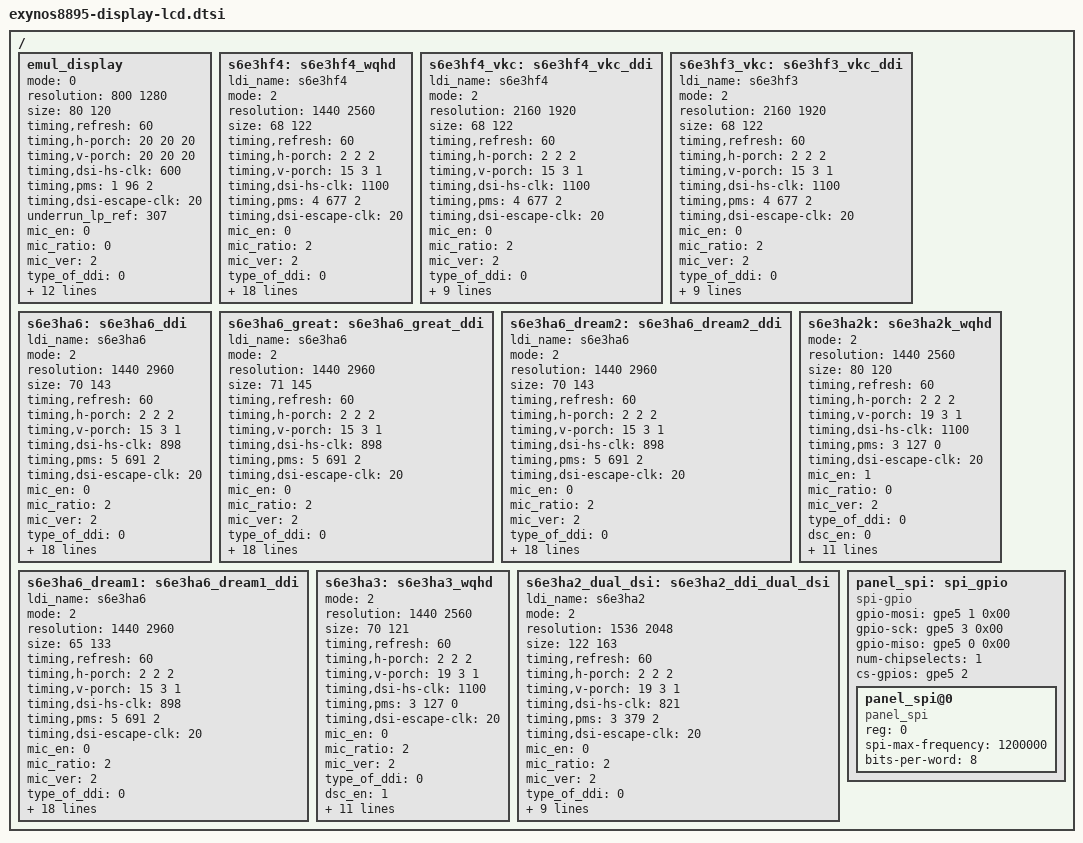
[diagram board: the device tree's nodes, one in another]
/*
 * SAMSUNG LCD Panel Device Tree Source
 *
 * Copyright (c) 2016 Samsung Electronics Co., Ltd.
 *		http://www.samsung.com
 *
 * This program is free software; you can redistribute it and/or modify
 * it under the terms of the GNU General Public License version 2 as
 * published by the Free Software Foundation.
*/

/ {
	emul_display: emul_display {
		mode = <0>; /* 0: video mode, 1: DP command mode, 2: MIPI command mode */
		resolution = <800 1280>;
		size = <80 120>;
		timing,refresh = <60>;
		timing,h-porch = <20 20 20>;
		timing,v-porch = <20 20 20>;
		timing,dsi-hs-clk = <600>;
		/* TODO : pms value to be set */
		timing,pms = <1 96 2>;
		timing,dsi-escape-clk = <20>;
		underrun_lp_ref = <307>;
		mic_en = <0>;		/* 0: Disable, 1: Enable */
		mic_ratio = <0>;	/* 0: 1/2 mic, 1: 1/3 mic */
		mic_ver = <2>;		/* 0: mic v1.1, 1: v1.2, 2: v2.0 */
		type_of_ddi = <0>;	/* 0: Samsung Mobile, 1: MAGNA, 2: Normal(Etc) */
		dsc_en = <0>;		/* 0: Disable, 1: Enable */
		dsc_cnt = <0>;		/* used DSC count */
		dsc_slice_num = <0>;	/* count of dsc slice */
		data_lane = <4>;	/* number of using data lane */
		cmd_underrun_lp_ref = <1203>;	/* for underrun detect at command mode*/
		vt_compensation = <2871>;	/* for underrun detect at video mode*/
		dsu_en = <0>;
		hdr_num = <0>;		/* max: 4 */
		hdr_type = <0 0 0 0>;	/* 1: DOLBY_VISION, 2: HDR10, 3: HLG */
		hdr_max_luma = <0>;		/* 0 */
		hdr_max_avg_luma = <0>;	/* 0 */
		hdr_min_luma = <0>;		/* 0.0000 */
	};

	s6e3hf4: s6e3hf4_wqhd {
		ldi_name = "s6e3hf4";
		mode = <2>;		/* 0: video mode, 1: DP command mode, 2: MIPI command mode */
		resolution = <1440 2560>;
		size = <68 122>;
		timing,refresh = <60>;
		timing,h-porch = <2 2 2>;
		timing,v-porch = <15 3 1>;
		timing,dsi-hs-clk = <1100>;
		timing,pms = <4 677 2>;
		timing,dsi-escape-clk = <20>;
		mic_en = <0>;		/* 0: Disable, 1: Enable */
		mic_ratio = <2>;	/* 0: 1/2 mic, 1: 1/3 mic */
		mic_ver = <2>;		/* 0: mic v1.1, 1: v1.2, 2: v2.0 */
		type_of_ddi = <0>;	/* 0: Samsung Mobile, 1: MAGNA, 2: Normal(Etc) */
		dsc_en = <1>;		/* 0: Disable, 1: Enable */
		dsc_cnt = <2>;		/* used DSC count */
		dsc_slice_num = <4>;	/* count of dsc slice */
		dsc_slice_h = <64>;	/* height of dsc slice */
		data_lane = <4>;	/* number of using data lane */
		cmd_underrun_lp_ref = <5629>;	/* for underrun detect*/
		dsu_en = <1>;
		dsu_number = <3>;
		dsu_width = <1440 1080 720>;
		dsu_height = <2560 1920 1280>;
		dsu_dsc_width = <720 540 360>;
		dsu_dsc_height = <64 64 128>;
		dsu_dsc_en = <1 1 1>;
		hdr_num = <1>;		/* max: 4 */
		hdr_type = <2 0 0 0>;	/* 1: DOLBY_VISION, 2: HDR10, 3: HLG */
		hdr_max_luma = <5400000>;		/* 540 */
		hdr_max_avg_luma = <1200000>;	/* 120 */
		hdr_min_luma = <5>;				/* 0.0005 */
	};

	s6e3hf4_vkc: s6e3hf4_vkc_ddi {
		ldi_name = "s6e3hf4";
		mode = <2>;		/* 0: video mode, 1: DP command mode, 2: MIPI command mode */
		resolution = <2160 1920>;
		size = <68 122>;
		timing,refresh = <60>;
		timing,h-porch = <2 2 2>;
		timing,v-porch = <15 3 1>;
		timing,dsi-hs-clk = <1100>;
		timing,pms = <4 677 2>;
		timing,dsi-escape-clk = <20>;
		mic_en = <0>;		/* 0: Disable, 1: Enable */
		mic_ratio = <2>;	/* 0: 1/2 mic, 1: 1/3 mic */
		mic_ver = <2>;		/* 0: mic v1.1, 1: v1.2, 2: v2.0 */
		type_of_ddi = <0>;	/* 0: Samsung Mobile, 1: MAGNA, 2: Normal(Etc) */
		dsc_en = <1>;		/* 0: Disable, 1: Enable */
		dsc_cnt = <2>;		/* used DSC count */
		dsc_slice_num = <2>;	/* count of dsc slice */
		dsc_slice_h = <32>;	/* height of dsc slice */
		data_lane = <4>;	/* number of using data lane */
		cmd_underrun_lp_ref = <5629>;	/* for underrun detect*/
		dsu_en = <0>;
		op_mode = <1>; /*0:Single Display + Single DSI, 1: Dual Display + Dual DSI, 2 : single Display + Dual DSI*/
		ss_path_swap = <1>;
	};


	s6e3hf3_vkc: s6e3hf3_vkc_ddi {
		ldi_name = "s6e3hf3";
		mode = <2>;		/* 0: video mode, 1: DP command mode, 2: MIPI command mode */
		resolution = <2160 1920>;
		size = <68 122>;
		timing,refresh = <60>;
		timing,h-porch = <2 2 2>;
		timing,v-porch = <15 3 1>;
		timing,dsi-hs-clk = <1100>;
		timing,pms = <4 677 2>;
		timing,dsi-escape-clk = <20>;
		mic_en = <0>;		/* 0: Disable, 1: Enable */
		mic_ratio = <2>;	/* 0: 1/2 mic, 1: 1/3 mic */
		mic_ver = <2>;		/* 0: mic v1.1, 1: v1.2, 2: v2.0 */
		type_of_ddi = <0>;	/* 0: Samsung Mobile, 1: MAGNA, 2: Normal(Etc) */
		dsc_en = <0>;		/* 0: Disable, 1: Enable */
		dsc_cnt = <2>;		/* used DSC count */
		dsc_slice_num = <2>;	/* count of dsc slice */
		dsc_slice_h = <32>;	/* height of dsc slice */
		data_lane = <4>;	/* number of using data lane */
		cmd_underrun_lp_ref = <5629>;	/* for underrun detect*/
		dsu_en = <0>;
		op_mode = <1>; /*0:Single Display + Single DSI, 1: Dual Display + Dual DSI, 2 : single Display + Dual DSI*/
		ss_path_swap = <1>;
	};


	s6e3ha6: s6e3ha6_ddi {
		ldi_name = "s6e3ha6";
		mode = <2>;		/* 0: video mode, 1: DP command mode, 2: MIPI command mode */
		resolution = <1440 2960>;
		size = <70 143>;
		timing,refresh = <60>;
		timing,h-porch = <2 2 2>;
		timing,v-porch = <15 3 1>;
		timing,dsi-hs-clk = <898>;
		timing,pms = <5 691 2>;
		timing,dsi-escape-clk = <20>;
		mic_en = <0>;		/* 0: Disable, 1: Enable */
		mic_ratio = <2>;	/* 0: 1/2 mic, 1: 1/3 mic */
		mic_ver = <2>;		/* 0: mic v1.1, 1: v1.2, 2: v2.0 */
		type_of_ddi = <0>;	/* 0: Samsung Mobile, 1: MAGNA, 2: Normal(Etc) */
		dsc_en = <1>;		/* 0: Disable, 1: Enable */
		dsc_cnt = <2>;		/* used DSC count */
		dsc_slice_num = <2>;	/* count of dsc slice */
		dsc_slice_h = <40>;	/* height of dsc slice */
		data_lane = <4>;	/* number of using data lane */
		cmd_underrun_lp_ref = <3022>;	/* for underrun detect*/
		dsu_en = <1>;
		dsu_number = <3>;
		dsu_width = <1440 1080 720>;
		dsu_height = <2960 2220 1480>;
		dsu_dsc_width = <720 540 360>;
		dsu_dsc_height = <40 30 74>;
		dsu_dsc_en = <1 1 0>;
		hdr_num = <1>;		/* max: 4 */
		hdr_type = <2 0 0 0>;	/* 1: DOLBY_VISION, 2: HDR10, 3: HLG */
		hdr_max_luma = <5400000>;		/* 540 */
		hdr_max_avg_luma = <1200000>;	/* 120 */
		hdr_min_luma = <5>;				/* 0.0005 */
	};

	s6e3ha6_great: s6e3ha6_great_ddi {
		ldi_name = "s6e3ha6";
		mode = <2>;		/* 0: video mode, 1: DP command mode, 2: MIPI command mode */
		resolution = <1440 2960>;
		size = <71 145>;
		timing,refresh = <60>;
		timing,h-porch = <2 2 2>;
		timing,v-porch = <15 3 1>;
		timing,dsi-hs-clk = <898>;
		timing,pms = <5 691 2>;
		timing,dsi-escape-clk = <20>;
		mic_en = <0>;		/* 0: Disable, 1: Enable */
		mic_ratio = <2>;	/* 0: 1/2 mic, 1: 1/3 mic */
		mic_ver = <2>;		/* 0: mic v1.1, 1: v1.2, 2: v2.0 */
		type_of_ddi = <0>;	/* 0: Samsung Mobile, 1: MAGNA, 2: Normal(Etc) */
		dsc_en = <1>;		/* 0: Disable, 1: Enable */
		dsc_cnt = <2>;		/* used DSC count */
		dsc_slice_num = <2>;	/* count of dsc slice */
		dsc_slice_h = <40>;	/* height of dsc slice */
		data_lane = <4>;	/* number of using data lane */
		cmd_underrun_lp_ref = <3022>;	/* for underrun detect*/
		dsu_en = <1>;
		dsu_number = <3>;
		dsu_width = <1440 1080 720>;
		dsu_height = <2960 2220 1480>;
		dsu_dsc_width = <720 540 360>;
		dsu_dsc_height = <40 30 74>;
		dsu_dsc_en = <1 1 0>;
		hdr_num = <1>;		/* max: 4 */
		hdr_type = <2 0 0 0>;	/* 1: DOLBY_VISION, 2: HDR10, 3: HLG */
		hdr_max_luma = <5400000>;		/* 540 */
		hdr_max_avg_luma = <1200000>;	/* 120 */
		hdr_min_luma = <5>;				/* 0.0005 */
	};


	s6e3ha6_dream2: s6e3ha6_dream2_ddi {
		ldi_name = "s6e3ha6";
		mode = <2>;		/* 0: video mode, 1: DP command mode, 2: MIPI command mode */
		resolution = <1440 2960>;
		size = <70 143>;
		timing,refresh = <60>;
		timing,h-porch = <2 2 2>;
		timing,v-porch = <15 3 1>;
		timing,dsi-hs-clk = <898>;
		timing,pms = <5 691 2>;
		timing,dsi-escape-clk = <20>;
		mic_en = <0>;		/* 0: Disable, 1: Enable */
		mic_ratio = <2>;	/* 0: 1/2 mic, 1: 1/3 mic */
		mic_ver = <2>;		/* 0: mic v1.1, 1: v1.2, 2: v2.0 */
		type_of_ddi = <0>;	/* 0: Samsung Mobile, 1: MAGNA, 2: Normal(Etc) */
		dsc_en = <1>;		/* 0: Disable, 1: Enable */
		dsc_cnt = <2>;		/* used DSC count */
		dsc_slice_num = <2>;	/* count of dsc slice */
		dsc_slice_h = <40>;	/* height of dsc slice */
		data_lane = <4>;	/* number of using data lane */
		cmd_underrun_lp_ref = <3022>;	/* for underrun detect*/
		dsu_en = <1>;
		dsu_number = <3>;
		dsu_width = <1440 1080 720>;
		dsu_height = <2960 2220 1480>;
		dsu_dsc_width = <720 540 360>;
		dsu_dsc_height = <40 30 74>;
		dsu_dsc_en = <1 1 0>;
		hdr_num = <1>;		/* max: 4 */
		hdr_type = <2 0 0 0>;	/* 1: DOLBY_VISION, 2: HDR10, 3: HLG */
		hdr_max_luma = <5400000>;		/* 540 */
		hdr_max_avg_luma = <1200000>;	/* 120 */
		hdr_min_luma = <5>;				/* 0.0005 */
	};

	s6e3ha6_dream1: s6e3ha6_dream1_ddi {
		ldi_name = "s6e3ha6";
		mode = <2>;		/* 0: video mode, 1: DP command mode, 2: MIPI command mode */
		resolution = <1440 2960>;
		size = <65 133>;
		timing,refresh = <60>;
		timing,h-porch = <2 2 2>;
		timing,v-porch = <15 3 1>;
		timing,dsi-hs-clk = <898>;
		timing,pms = <5 691 2>;
		timing,dsi-escape-clk = <20>;
		mic_en = <0>;		/* 0: Disable, 1: Enable */
		mic_ratio = <2>;	/* 0: 1/2 mic, 1: 1/3 mic */
		mic_ver = <2>;		/* 0: mic v1.1, 1: v1.2, 2: v2.0 */
		type_of_ddi = <0>;	/* 0: Samsung Mobile, 1: MAGNA, 2: Normal(Etc) */
		dsc_en = <1>;		/* 0: Disable, 1: Enable */
		dsc_cnt = <2>;		/* used DSC count */
		dsc_slice_num = <2>;	/* count of dsc slice */
		dsc_slice_h = <40>;	/* height of dsc slice */
		data_lane = <4>;	/* number of using data lane */
		cmd_underrun_lp_ref = <3022>;	/* for underrun detect*/
		dsu_en = <1>;
		dsu_number = <3>;
		dsu_width = <1440 1080 720>;
		dsu_height = <2960 2220 1480>;
		dsu_dsc_width = <720 540 360>;
		dsu_dsc_height = <40 30 74>;
		dsu_dsc_en = <1 1 0>;
		hdr_num = <1>;		/* max: 4 */
		hdr_type = <2 0 0 0>;	/* 1: DOLBY_VISION, 2: HDR10, 3: HLG */
		hdr_max_luma = <5400000>;		/* 540 */
		hdr_max_avg_luma = <1200000>;	/* 120 */
		hdr_min_luma = <5>;				/* 0.0005 */
	};

	s6e3ha2k: s6e3ha2k_wqhd {
		mode = <2>;		/* 0: video mode, 1: DP command mode, 2: MIPI command mode */
		resolution = <1440 2560>;
		size = <80 120>;
		timing,refresh = <60>;
		timing,h-porch = <2 2 2>;
		timing,v-porch = <19 3 1>;
		timing,dsi-hs-clk = <1100>;
		timing,pms = <3 127 0>;
		timing,dsi-escape-clk = <20>;
		mic_en = <1>;		/* 0: Disable, 1: Enable */
		mic_ratio = <0>;	/* 0: 1/2 mic, 1: 1/3 mic */
		mic_ver = <2>;		/* 0: mic v1.1, 1: v1.2, 2: v2.0 */
		type_of_ddi = <0>;	/* 0: Samsung Mobile, 1: MAGNA, 2: Normal(Etc) */
		dsc_en = <0>;		/* 0: Disable, 1: Enable */
		dsc_cnt = <0>;		/* used DSC count */
		dsc_slice_num = <0>;	/* count of dsc slice */
		dsc_slice_h = <0>;	/* height of dsc slice */
		data_lane = <4>;	/* number of using data lane */
		cmd_underrun_lp_ref = <1203>;	/* for underrun detect*/
		dsu_en = <0>;
		hdr_num = <1>;		/* max: 4 */
		hdr_type = <2 0 0 0>;	/* 1: DOLBY_VISION, 2: HDR10, 3: HLG */
		hdr_max_luma = <5400000>;		/* 540 */
		hdr_max_avg_luma = <1200000>;	/* 120 */
		hdr_min_luma = <5>;				/* 0.0005 */
	};

	s6e3ha3: s6e3ha3_wqhd {
		mode = <2>;		/* 0: video mode, 1: DP command mode, 2: MIPI command mode */
		resolution = <1440 2560>;
		size = <70 121>;
		timing,refresh = <60>;
		timing,h-porch = <2 2 2>;
		timing,v-porch = <19 3 1>;
		timing,dsi-hs-clk = <1100>;
		timing,pms = <3 127 0>;
		timing,dsi-escape-clk = <20>;
		mic_en = <0>;		/* 0: Disable, 1: Enable */
		mic_ratio = <2>;	/* 0: 1/2 mic, 1: 1/3 mic */
		mic_ver = <2>;		/* 0: mic v1.1, 1: v1.2, 2: v2.0 */
		type_of_ddi = <0>;	/* 0: Samsung Mobile, 1: MAGNA, 2: Normal(Etc) */
		dsc_en = <1>;		/* 0: Disable, 1: Enable */
		dsc_cnt = <1>;		/* used DSC count */
		dsc_slice_num = <1>;	/* count of dsc slice */
		dsc_slice_h = <32>;	/* height of dsc slice */
		data_lane = <4>;	/* number of using data lane */
		cmd_underrun_lp_ref = <1203>;	/* for underrun detect*/
		dsu_en = <0>;
		hdr_num = <1>;		/* max: 4 */
		hdr_type = <2 0 0 0>;	/* 1: DOLBY_VISION, 2: HDR10, 3: HLG */
		hdr_max_luma = <5400000>;		/* 540 */
		hdr_max_avg_luma = <1200000>;	/* 120 */
		hdr_min_luma = <5>;				/* 0.0005 */
	};


	s6e3ha2_dual_dsi: s6e3ha2_ddi_dual_dsi {
		ldi_name = "s6e3ha2";
		mode = <2>;		/* 0: video mode, 1: DP command mode, 2: MIPI command mode */
		resolution = <1536 2048>;
		size = <122 163>;
		timing,refresh = <60>;
		timing,h-porch = <2 2 2>;
		timing,v-porch = <19 3 1>;
		timing,dsi-hs-clk = <821>;
		timing,pms = <3 379 2>;
		timing,dsi-escape-clk = <20>;
		mic_en = <0>;		/* 0: Disable, 1: Enable */
		mic_ratio = <2>;	/* 0: 1/2 mic, 1: 1/3 mic */
		mic_ver = <2>;		/* 0: mic v1.1, 1: v1.2, 2: v2.0 */
		type_of_ddi = <0>;	/* 0: Samsung Mobile, 1: MAGNA, 2: Normal(Etc) */
		dsc_en = <0>;		/* 0: Disable, 1: Enable */
		dsc_cnt = <1>;		/* used DSC count */
		dsc_slice_num = <1>;	/* count of dsc slice */
		dsc_slice_h = <32>;	/* height of dsc slice */
		data_lane = <4>;	/* number of using data lane */
		cmd_underrun_lp_ref = <3482>;	/* for underrun detect*/
		dsu_en = <0>;
		/* operating mode
		0 : Single Display + Single DSI
		1 : Dual Display + Dual DSI
		2 : Dual Display + Single DSI */
		op_mode = <2>;
		ss_path_swap = <0>;
	};
	panel_spi: spi_gpio {
		compatible = "spi-gpio";
		#address-cells = <1>;
		#size-cells = <0>;
		gpio-mosi = <&gpe5 1 0x00>;
		gpio-sck = <&gpe5 3 0x00>;
		gpio-miso = <&gpe5 0 0x00>;
		num-chipselects = <1>;
		cs-gpios = <&gpe5 2 0x00>;

		panel_spi@0 {
			compatible = "panel_spi";
			reg = <0>;
			spi-max-frequency = <1200000>;
			bits-per-word = <8>;
		};
	};
};
